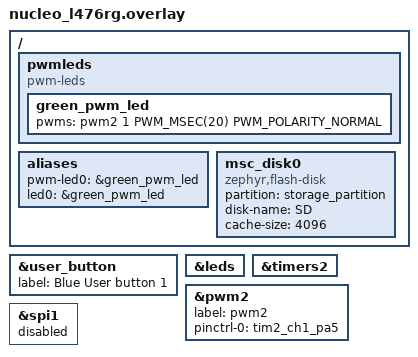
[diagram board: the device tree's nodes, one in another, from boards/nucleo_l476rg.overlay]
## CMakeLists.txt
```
cmake_minimum_required(VERSION 3.20.0)

# set(BOARD nucleo_l476rg)
set(BOARD nrf52840dk/nrf52840)
# set(DTC_OVERLAY_FILE app.overlay)

find_package(Zephyr REQUIRED HINTS $ENV{ZEPHYR_BASE})

project(l4z)

target_sources(app PRIVATE src/main.c)
```

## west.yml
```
manifest:
  remotes:
    - name: zephyrproject-rtos
      url-base: https://github.com/zephyrproject-rtos

  projects:
    - name: zephyr
      remote: zephyrproject-rtos
      revision: v3.6.0
      import: true
    # - name: l4z
    #   url: your-git-server
    #   revision: SOME_SHA_OR_BRANCH_OR_TAG
  self:
    path: application
```

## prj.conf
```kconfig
# CONFIG_BOOT_DELAY=1

CONFIG_GPIO=y
CONFIG_LED=y
CONFIG_LED_GPIO=y

# Uncomment one to make it work
CONFIG_SHELL=y
CONFIG_LOG=y
```

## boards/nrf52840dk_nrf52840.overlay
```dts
// / {
// 	leds {
// // 	// status = "disabled";
// 		status = "okay";
// 	};

// 	pwmleds {
// 		status = "okay";
// 	};
// };
```

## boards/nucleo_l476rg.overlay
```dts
// "Standard" pwm definition from other nucleo boards

/ {
	pwmleds: pwmleds {
		compatible = "pwm-leds";
		green_pwm_led: green_pwm_led {
			pwms = <&pwm2 1 PWM_MSEC(20) PWM_POLARITY_NORMAL>;
		};
	};

	aliases {
		pwm-led0 = &green_pwm_led;
	};
};


// Replace GPIO LED with PWM LED
/delete-node/ &{/leds/led_2};
/ {
	aliases {
		/delete-property/ led0;
		led0 = &green_pwm_led;
	};
};


/ {
	msc_disk0 {
		status="okay";
		compatible = "zephyr,flash-disk";
		partition = <&storage_partition>;
		disk-name = "SD";
		/* cache-size == page erase size */
		cache-size = <4096>;
	};
};


&user_button {
	status = "okay";
	label = "Blue User button 1";
};

&leds {
	// status = "disabled";
};

&timers2 {
	status = "okay";
};
&pwm2 {
	status = "okay";
	label = "pwm2";
	pinctrl-0 = < &tim2_ch1_pa5 >;
};
&pwmleds {
	status = "okay";
};

&spi1 {
	status = "disabled";
};
```

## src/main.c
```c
#include <zephyr/kernel.h>
#include <zephyr/drivers/led.h>

#define LED_GPIO_NODE_ID DT_COMPAT_GET_ANY_STATUS_OKAY(gpio_leds)
static const struct device *led_gpio = DEVICE_DT_GET(LED_GPIO_NODE_ID);


int main(void) {
	if (!device_is_ready(led_gpio)) {
		printk("Device %s is not ready", led_gpio->name);
		return 0;
	}

	led_on(led_gpio, 0);
	printk("before sleep\n");

	k_msleep(100);
	led_on(led_gpio, 1);
	printk("after 100ms sleep\n");

	k_msleep(1000);
	led_on(led_gpio, 2);
	printk("after sleep\n");

    return 0;
}
```
